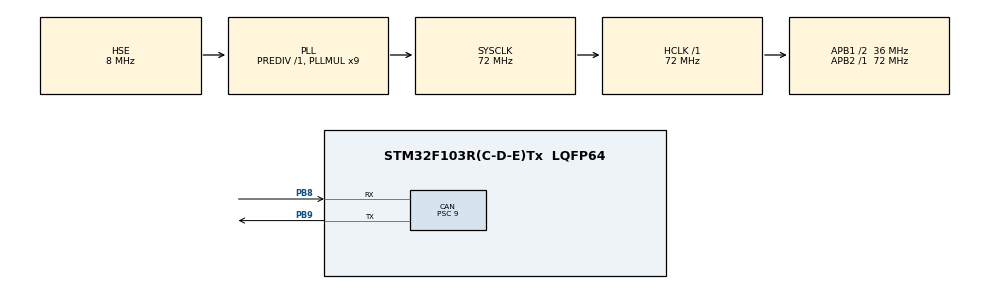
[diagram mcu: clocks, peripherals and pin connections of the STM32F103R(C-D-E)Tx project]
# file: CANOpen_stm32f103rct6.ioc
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CAN.ABOM=ENABLE
CAN.BS1=CAN_BS1_5TQ
CAN.BS2=CAN_BS2_2TQ
CAN.CalculateBaudRate=500000
CAN.CalculateTimeBit=2000
CAN.CalculateTimeQuantum=250.0
CAN.NART=ENABLE
CAN.Prescaler=9
Mcu.Family=STM32F1
Mcu.Name=STM32F103R(C-D-E)Tx
Mcu.Package=LQFP64
NVIC.CAN1_SCE_IRQn=true\:5\:0\:true\:false\:true\:true\:true\:true
NVIC.PriorityGroup=NVIC_PRIORITYGROUP_4
NVIC.TIM6_IRQn=true\:5\:0\:true\:false\:true\:true\:true\:true
NVIC.USB_LP_CAN1_RX0_IRQn=true\:5\:0\:true\:false\:true\:true\:true\:true
PB8.Mode=CAN_Activate
PB8.Signal=CAN_RX
PB9.Mode=CAN_Activate
PB9.Signal=CAN_TX
PD0-OSC_IN.Mode=HSE-External-Oscillator
PD0-OSC_IN.Signal=RCC_OSC_IN
PD1-OSC_OUT.Mode=HSE-External-Oscillator
PD1-OSC_OUT.Signal=RCC_OSC_OUT
ProjectManager.HeapSize=0x200
ProjectManager.StackSize=0x400
ProjectManager.TargetToolchain=STM32CubeIDE
RCC.AHBFreq_Value=72000000
RCC.APB1CLKDivider=RCC_HCLK_DIV2
RCC.APB1Freq_Value=36000000
RCC.APB1TimFreq_Value=72000000
RCC.APB2Freq_Value=72000000
RCC.APB2TimFreq_Value=72000000
RCC.HCLKFreq_Value=72000000
RCC.PLLMUL=RCC_PLL_MUL9
RCC.PLLSourceVirtual=RCC_PLLSOURCE_HSE
RCC.SYSCLKFreq_VALUE=72000000
RCC.SYSCLKSource=RCC_SYSCLKSOURCE_PLLCLK
RCC.USBFreq_Value=72000000
VP_SYS_VS_ND.Mode=No_Debug
VP_TIM6_VS_ClockSourceINT.Mode=Enable_Timer
board=custom

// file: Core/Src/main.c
/* USER CODE BEGIN Header */
/**
  ******************************************************************************
  * @file           : main.c
  * @brief          : Main program body
  ******************************************************************************
  * @attention
  *
  * Copyright (c) 2025 STMicroelectronics.
  * All rights reserved.
  *
  * This software is licensed under terms that can be found in the LICENSE file
  * in the root directory of this software component.
  * If no LICENSE file comes with this software, it is provided AS-IS.
  *
  ******************************************************************************
  */
/* USER CODE END Header */
#include "main.h"
#include "can.h"
#include "tim.h"
#include "gpio.h"

/* USER CODE BEGIN Includes */
#include "CO_app_STM32.h"
#include "CO_driver.h"       // CANopen驱动头文件
#include "CO_ODinterface.h"  // 对象字典接口
#include "CO_Emergency.h"    // 紧急对象
/* USER CODE END Includes */

void SystemClock_Config(void);

int main(void)
{

  /* MCU Configuration--------------------------------------------------------*/

  /* Reset of all peripherals, Initializes the Flash interface and the Systick. */
  HAL_Init();

  /* Configure the system clock */
  SystemClock_Config();

  /* Initialize all configured peripherals */
  MX_GPIO_Init();
  MX_CAN_Init();
  MX_TIM6_Init();
  /* USER CODE BEGIN 2 */
  CANopenNodeSTM32 canopenNodeSTM32;
  canopenNodeSTM32.CANHandle = &hcan;
  canopenNodeSTM32.HWInitFunction = MX_CAN_Init; // CubeMX生成的CAN初始化函数
  canopenNodeSTM32.timerHandle = &htim6;          // 1ms定时器
  canopenNodeSTM32.desiredNodeID = 1;             // 节点ID
  canopenNodeSTM32.baudrate = 500;                // 125kbps
  canopen_app_init(&canopenNodeSTM32);
  /* USER CODE END 2 */

  /* Infinite loop */
  /* USER CODE BEGIN WHILE */
  while (1)
  {
	  canopen_app_process();
    /* USER CODE END WHILE */

  }
}

void SystemClock_Config(void)
{
  RCC_OscInitTypeDef RCC_OscInitStruct = {0};
  RCC_ClkInitTypeDef RCC_ClkInitStruct = {0};

  /** Initializes the RCC Oscillators according to the specified parameters
  * in the RCC_OscInitTypeDef structure.
  */
  RCC_OscInitStruct.OscillatorType = RCC_OSCILLATORTYPE_HSE;
  RCC_OscInitStruct.HSEState = RCC_HSE_ON;
  RCC_OscInitStruct.HSEPredivValue = RCC_HSE_PREDIV_DIV1;
  RCC_OscInitStruct.HSIState = RCC_HSI_ON;
  RCC_OscInitStruct.PLL.PLLState = RCC_PLL_ON;
  RCC_OscInitStruct.PLL.PLLSource = RCC_PLLSOURCE_HSE;
  RCC_OscInitStruct.PLL.PLLMUL = RCC_PLL_MUL9;
  if (HAL_RCC_OscConfig(&RCC_OscInitStruct) != HAL_OK)
  {
    Error_Handler();
  }

  /** Initializes the CPU, AHB and APB buses clocks
  */
  RCC_ClkInitStruct.ClockType = RCC_CLOCKTYPE_HCLK|RCC_CLOCKTYPE_SYSCLK
                              |RCC_CLOCKTYPE_PCLK1|RCC_CLOCKTYPE_PCLK2;
  RCC_ClkInitStruct.SYSCLKSource = RCC_SYSCLKSOURCE_PLLCLK;
  RCC_ClkInitStruct.AHBCLKDivider = RCC_SYSCLK_DIV1;
  RCC_ClkInitStruct.APB1CLKDivider = RCC_HCLK_DIV2;
  RCC_ClkInitStruct.APB2CLKDivider = RCC_HCLK_DIV1;

  if (HAL_RCC_ClockConfig(&RCC_ClkInitStruct, FLASH_LATENCY_2) != HAL_OK)
  {
    Error_Handler();
  }
}

void Error_Handler(void)
{
  __disable_irq();
  while (1)
  {
  }
}
